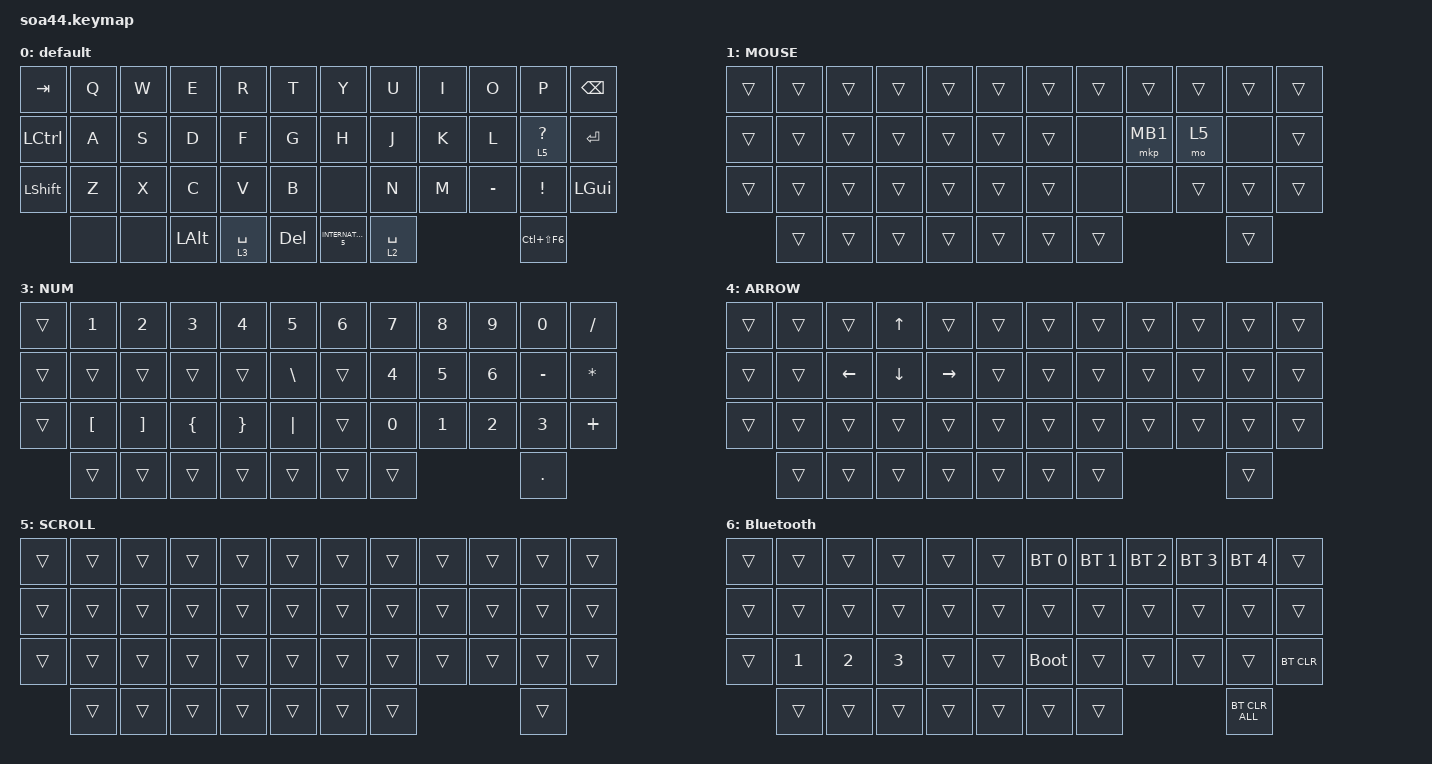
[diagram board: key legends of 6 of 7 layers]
#include <behaviors.dtsi>
#include <dt-bindings/zmk/bt.h>
#include <dt-bindings/zmk/keys.h>
#include <dt-bindings/zmk/pointing.h>

&mt {
    flavor = "balanced";
    quick-tap-ms = <0>;
};

/ {
    combos {
        compatible = "zmk,combos";

        tab {
            bindings = <&kp TAB>;
            key-positions = <11 12>;
        };

        shift_tab {
            bindings = <&kp LS(TAB)>;
            key-positions = <12 13>;
        };

        muhennkann {
            bindings = <&to_layer_0 INT_MUHENKAN>;
            key-positions = <11 10>;
        };

        double_quotation {
            bindings = <&kp DOUBLE_QUOTES>;
            key-positions = <20 21>;
        };

        eq {
            bindings = <&kp EQUAL>;
            key-positions = <24 25>;
        };
    };

    macros {
        to_layer_0: to_layer_0 {
            compatible = "zmk,behavior-macro-one-param";
            #binding-cells = <1>;
            bindings = <&to 0 &macro_param_1to1 &kp MACRO_PLACEHOLDER>;
            label = "TO_LAYER_0";
        };
    };

    behaviors {
        lt_to_layer_0: lt_to_layer_0 {
            compatible = "zmk,behavior-hold-tap";
            label = "LAYER_TAP_TO_0";
            bindings = <&mo>, <&to_layer_0>;

            #binding-cells = <2>;
            tapping-term-ms = <200>;
        };
    };

    keymap {
        compatible = "zmk,keymap";

        default {
            bindings = <
&kp TAB         &kp Q  &kp W  &kp E         &kp R        &kp T       &kp Y                &kp U        &kp I  &kp O      &kp P            &kp BACKSPACE
&kp LCTRL       &kp A  &kp S  &kp D         &kp F        &kp G       &kp H                &kp J        &kp K  &kp L      &lt 5 QUESTION   &kp ENTER
&kp LEFT_SHIFT  &kp Z  &kp X  &kp C         &kp V        &kp B       &none                &kp N        &kp M  &kp MINUS  &kp EXCLAMATION  &kp LEFT_GUI
                &none  &none  &kp LEFT_ALT  &lt 3 SPACE  &kp DELETE  &kp INTERNATIONAL_5  &lt 2 SPACE                    &kp LC(LS(F6))
            >;
        };

        MOUSE {
            bindings = <
&trans  &trans  &trans  &trans  &trans  &trans  &trans  &trans  &trans    &trans  &trans  &trans
&trans  &trans  &trans  &trans  &trans  &trans  &trans  &none   &mkp MB1  &mo 5   &none   &trans
&trans  &trans  &trans  &trans  &trans  &trans  &trans  &none   &none     &trans  &trans  &trans
        &trans  &trans  &trans  &trans  &trans  &trans  &trans                    &trans
            >;
        };

        FUNCTION {
bindings = <
&kp ESC   &kp F11  &kp F2   &td_pass  &td_mail  &kp SEMI   &kp ESC   &kp HOME &none   &kp END   &kp LC(R) &kp LC(W)
&trans    &kp F10  &kp F6   &td_brc   &td_qot   &kp LS(BSLS) &kp LEFT  &kp DOWN &kp UP   &kp RIGHT &kp C_VOL_UP &trans
&trans    &none    &none    &none     &kp GRAVE &kp BSLS    &kp COMMA &kp DOT  &kp SLASH &kp LS(GRAVE) &kp C_VOL_DN &trans
          &trans  &trans   &trans    &trans    &trans      &trans   &trans   &trans   &trans   &trans
            >;
        };

        NUM {
            bindings = <
&trans  &kp N1            &kp N2             &kp N3          &kp N4           &kp N5         &kp N6  &kp N7  &kp N8  &kp N9  &kp N0      &kp SLASH
&trans  &trans            &trans             &trans          &trans           &kp BACKSLASH  &trans  &kp N4  &kp N5  &kp N6  &kp MINUS   &kp ASTERISK
&trans  &kp LEFT_BRACKET  &kp RIGHT_BRACKET  &kp LEFT_BRACE  &kp RIGHT_BRACE  &kp PIPE       &trans  &kp N0  &kp N1  &kp N2  &kp N3      &kp PLUS
        &trans            &trans             &trans          &trans           &trans         &trans  &trans                  &kp PERIOD
            >;
        };

        ARROW {
            bindings = <
&trans  &trans  &trans    &kp UP    &trans     &trans  &trans  &trans  &trans  &trans  &trans  &trans
&trans  &trans  &kp LEFT  &kp DOWN  &kp RIGHT  &trans  &trans  &trans  &trans  &trans  &trans  &trans
&trans  &trans  &trans    &trans    &trans     &trans  &trans  &trans  &trans  &trans  &trans  &trans
        &trans  &trans    &trans    &trans     &trans  &trans  &trans                  &trans
            >;
        };

        SCROLL {
            bindings = <
&trans  &trans  &trans  &trans  &trans  &trans  &trans  &trans  &trans  &trans  &trans  &trans
&trans  &trans  &trans  &trans  &trans  &trans  &trans  &trans  &trans  &trans  &trans  &trans
&trans  &trans  &trans  &trans  &trans  &trans  &trans  &trans  &trans  &trans  &trans  &trans
        &trans  &trans  &trans  &trans  &trans  &trans  &trans                  &trans
            >;
        };

        Bluetooth {
            bindings = <
&trans  &trans        &trans        &trans        &trans  &trans  &bt BT_SEL 0  &bt BT_SEL 1  &bt BT_SEL 2  &bt BT_SEL 3  &bt BT_SEL 4    &trans
&trans  &trans        &trans        &trans        &trans  &trans  &trans        &trans        &trans        &trans        &trans          &trans
&trans  &kp NUMBER_1  &kp NUMBER_2  &kp NUMBER_3  &trans  &trans  &bootloader   &trans        &trans        &trans        &trans          &bt BT_CLR
        &trans        &trans        &trans        &trans  &trans  &trans        &trans                                    &bt BT_CLR_ALL
            >;
        };
    };
};
